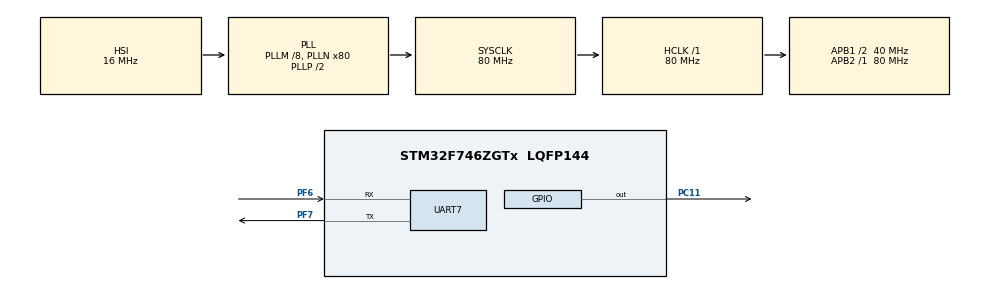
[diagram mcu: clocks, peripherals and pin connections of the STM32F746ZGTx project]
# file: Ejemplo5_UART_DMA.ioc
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Dma.Request0=UART7_RX
Dma.Request1=UART7_TX
Dma.UART7_RX.0.Direction=DMA_PERIPH_TO_MEMORY
Dma.UART7_RX.0.FIFOMode=DMA_FIFOMODE_DISABLE
Dma.UART7_RX.0.Instance=DMA1_Stream3
Dma.UART7_RX.0.MemDataAlignment=DMA_MDATAALIGN_BYTE
Dma.UART7_RX.0.MemInc=DMA_MINC_ENABLE
Dma.UART7_RX.0.Mode=DMA_NORMAL
Dma.UART7_RX.0.PeriphDataAlignment=DMA_PDATAALIGN_BYTE
Dma.UART7_RX.0.PeriphInc=DMA_PINC_DISABLE
Dma.UART7_RX.0.Priority=DMA_PRIORITY_LOW
Dma.UART7_TX.1.Direction=DMA_MEMORY_TO_PERIPH
Dma.UART7_TX.1.FIFOMode=DMA_FIFOMODE_DISABLE
Dma.UART7_TX.1.Instance=DMA1_Stream1
Dma.UART7_TX.1.MemDataAlignment=DMA_MDATAALIGN_BYTE
Dma.UART7_TX.1.MemInc=DMA_MINC_ENABLE
Dma.UART7_TX.1.Mode=DMA_NORMAL
Dma.UART7_TX.1.PeriphDataAlignment=DMA_PDATAALIGN_BYTE
Dma.UART7_TX.1.PeriphInc=DMA_PINC_DISABLE
Dma.UART7_TX.1.Priority=DMA_PRIORITY_LOW
Mcu.Family=STM32F7
Mcu.Name=STM32F746ZGTx
Mcu.Package=LQFP144
NVIC.DMA1_Stream1_IRQn=true\:0\:0\:false\:false\:true\:false\:true\:true
NVIC.DMA1_Stream3_IRQn=true\:0\:0\:false\:false\:true\:false\:true\:true
NVIC.PriorityGroup=NVIC_PRIORITYGROUP_4
NVIC.UART7_IRQn=true\:0\:0\:false\:false\:true\:true\:true\:true
PA13.Mode=Serial_Wire
PA13.Signal=SYS_JTMS-SWDIO
PA14.Mode=Serial_Wire
PA14.Signal=SYS_JTCK-SWCLK
PC11.Signal=GPIO_Output
PC14/OSC32_IN.Mode=LSE-External-Oscillator
PC14/OSC32_IN.Signal=RCC_OSC32_IN
PC15/OSC32_OUT.Mode=LSE-External-Oscillator
PC15/OSC32_OUT.Signal=RCC_OSC32_OUT
PF6.Mode=Asynchronous
PF6.Signal=UART7_RX
PF7.Mode=Asynchronous
PF7.Signal=UART7_TX
PH0/OSC_IN.Mode=HSE-External-Oscillator
PH0/OSC_IN.Signal=RCC_OSC_IN
PH1/OSC_OUT.Mode=HSE-External-Oscillator
PH1/OSC_OUT.Signal=RCC_OSC_OUT
ProjectManager.HeapSize=0x200
ProjectManager.StackSize=0x400
ProjectManager.TargetToolchain=STM32CubeIDE
RCC.48MHZClocksFreq_Value=24000000
RCC.AHBFreq_Value=80000000
RCC.APB1CLKDivider=RCC_HCLK_DIV2
RCC.APB1Freq_Value=40000000
RCC.APB1TimFreq_Value=80000000
RCC.APB2Freq_Value=80000000
RCC.APB2TimFreq_Value=80000000
RCC.CortexFreq_Value=80000000
RCC.HCLKFreq_Value=80000000
RCC.HSE_VALUE=8000000
RCC.HSI_VALUE=16000000
RCC.PLLM=8
RCC.PLLMUL=RCC_PLL_MUL9
RCC.PLLN=80
RCC.PRESCALERUSB=RCC_USBCLKSOURCE_PLL_DIV1_5
RCC.SYSCLKFreq_VALUE=80000000
RCC.SYSCLKSource=RCC_SYSCLKSOURCE_PLLCLK
RCC.SYSCLKSourceVirtual=RCC_SYSCLKSOURCE_PLLCLK
RCC.USBFreq_Value=80000000
RCC.VCOOutputFreq_Value=160000000
board=NUCLEO-F746ZG

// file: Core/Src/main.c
/* USER CODE BEGIN Header */
/**
  ******************************************************************************
  * @file           : main.c
  * @brief          : Main program body
  ******************************************************************************
  * @attention
  *
  * Copyright (c) 2023 STMicroelectronics.
  * All rights reserved.
  *
  * This software is licensed under terms that can be found in the LICENSE file
  * in the root directory of this software component.
  * If no LICENSE file comes with this software, it is provided AS-IS.
  *
  ******************************************************************************
  */
/* USER CODE END Header */
#include "main.h"

UART_HandleTypeDef huart7;
DMA_HandleTypeDef hdma_uart7_rx;
DMA_HandleTypeDef hdma_uart7_tx;

/* USER CODE BEGIN PV */
uint8_t Rx[1];
 uint8_t Tx_ACK[]="ACK OK";
/* USER CODE END PV */

void SystemClock_Config(void);
static void MX_GPIO_Init(void);
static void MX_DMA_Init(void);
static void MX_UART7_Init(void);

int main(void)
{

  /* MCU Configuration--------------------------------------------------------*/

  /* Reset of all peripherals, Initializes the Flash interface and the Systick. */
  HAL_Init();

  /* Configure the system clock */
  SystemClock_Config();

  /* Initialize all configured peripherals */
  MX_GPIO_Init();
  MX_DMA_Init();
  MX_UART7_Init();
  /* USER CODE BEGIN 2 */
  HAL_UART_Receive_DMA(&huart7, Rx, sizeof(Rx));
  /* USER CODE END 2 */

  /* Infinite loop */
  while (1)
  {

  }
}

void SystemClock_Config(void)
{
  RCC_OscInitTypeDef RCC_OscInitStruct = {0};
  RCC_ClkInitTypeDef RCC_ClkInitStruct = {0};

  /** Configure LSE Drive Capability
  */
  HAL_PWR_EnableBkUpAccess();

  /** Configure the main internal regulator output voltage
  */
  __HAL_RCC_PWR_CLK_ENABLE();
  __HAL_PWR_VOLTAGESCALING_CONFIG(PWR_REGULATOR_VOLTAGE_SCALE3);

  /** Initializes the RCC Oscillators according to the specified parameters
  * in the RCC_OscInitTypeDef structure.
  */
  RCC_OscInitStruct.OscillatorType = RCC_OSCILLATORTYPE_HSI;
  RCC_OscInitStruct.HSIState = RCC_HSI_ON;
  RCC_OscInitStruct.HSICalibrationValue = RCC_HSICALIBRATION_DEFAULT;
  RCC_OscInitStruct.PLL.PLLState = RCC_PLL_ON;
  RCC_OscInitStruct.PLL.PLLSource = RCC_PLLSOURCE_HSI;
  RCC_OscInitStruct.PLL.PLLM = 8;
  RCC_OscInitStruct.PLL.PLLN = 80;
  RCC_OscInitStruct.PLL.PLLP = RCC_PLLP_DIV2;
  RCC_OscInitStruct.PLL.PLLQ = 2;
  if (HAL_RCC_OscConfig(&RCC_OscInitStruct) != HAL_OK)
  {
    Error_Handler();
  }

  /** Initializes the CPU, AHB and APB buses clocks
  */
  RCC_ClkInitStruct.ClockType = RCC_CLOCKTYPE_HCLK|RCC_CLOCKTYPE_SYSCLK
                              |RCC_CLOCKTYPE_PCLK1|RCC_CLOCKTYPE_PCLK2;
  RCC_ClkInitStruct.SYSCLKSource = RCC_SYSCLKSOURCE_PLLCLK;
  RCC_ClkInitStruct.AHBCLKDivider = RCC_SYSCLK_DIV1;
  RCC_ClkInitStruct.APB1CLKDivider = RCC_HCLK_DIV2;
  RCC_ClkInitStruct.APB2CLKDivider = RCC_HCLK_DIV1;

  if (HAL_RCC_ClockConfig(&RCC_ClkInitStruct, FLASH_LATENCY_2) != HAL_OK)
  {
    Error_Handler();
  }
}

static void MX_UART7_Init(void)
{

  huart7.Instance = UART7;
  huart7.Init.BaudRate = 115200;
  huart7.Init.WordLength = UART_WORDLENGTH_8B;
  huart7.Init.StopBits = UART_STOPBITS_1;
  huart7.Init.Parity = UART_PARITY_NONE;
  huart7.Init.Mode = UART_MODE_TX_RX;
  huart7.Init.HwFlowCtl = UART_HWCONTROL_NONE;
  huart7.Init.OverSampling = UART_OVERSAMPLING_16;
  huart7.Init.OneBitSampling = UART_ONE_BIT_SAMPLE_DISABLE;
  huart7.AdvancedInit.AdvFeatureInit = UART_ADVFEATURE_NO_INIT;
  if (HAL_UART_Init(&huart7) != HAL_OK)
  {
    Error_Handler();
  }

}

static void MX_DMA_Init(void)
{

  /* DMA controller clock enable */
  __HAL_RCC_DMA1_CLK_ENABLE();

  /* DMA interrupt init */
  /* DMA1_Stream1_IRQn interrupt configuration */
  HAL_NVIC_SetPriority(DMA1_Stream1_IRQn, 0, 0);
  HAL_NVIC_EnableIRQ(DMA1_Stream1_IRQn);
  /* DMA1_Stream3_IRQn interrupt configuration */
  HAL_NVIC_SetPriority(DMA1_Stream3_IRQn, 0, 0);
  HAL_NVIC_EnableIRQ(DMA1_Stream3_IRQn);

}

static void MX_GPIO_Init(void)
{
  GPIO_InitTypeDef GPIO_InitStruct = {0};

  /* GPIO Ports Clock Enable */
  __HAL_RCC_GPIOC_CLK_ENABLE();
  __HAL_RCC_GPIOF_CLK_ENABLE();
  __HAL_RCC_GPIOH_CLK_ENABLE();
  __HAL_RCC_GPIOA_CLK_ENABLE();

  /*Configure GPIO pin Output Level */
  HAL_GPIO_WritePin(GPIOC, GPIO_PIN_11, GPIO_PIN_RESET);

  /*Configure GPIO pin : PC11 */
  GPIO_InitStruct.Pin = GPIO_PIN_11;
  GPIO_InitStruct.Mode = GPIO_MODE_OUTPUT_PP;
  GPIO_InitStruct.Pull = GPIO_NOPULL;
  GPIO_InitStruct.Speed = GPIO_SPEED_FREQ_LOW;
  HAL_GPIO_Init(GPIOC, &GPIO_InitStruct);

}

/* USER CODE BEGIN 4 */
void HAL_UART_RxCpltCallback(UART_HandleTypeDef *huart)
{
	if(huart->Instance==UART7){
				HAL_UART_Transmit_DMA(&huart7, Tx_ACK, sizeof(Tx_ACK));
			}
				switch (Rx[0]) {
				case '1':
					HAL_GPIO_WritePin(GPIOC, GPIO_PIN_11, GPIO_PIN_SET);
					break;
				case '0':
				HAL_GPIO_WritePin(GPIOC, GPIO_PIN_11, GPIO_PIN_RESET);
				    break;
				default:
					break;
				}
	     HAL_UART_Receive_DMA(&huart7, Rx, sizeof(Rx));

}
/* USER CODE END 4 */

void Error_Handler(void)
{
  __disable_irq();
  while (1)
  {
  }
}
